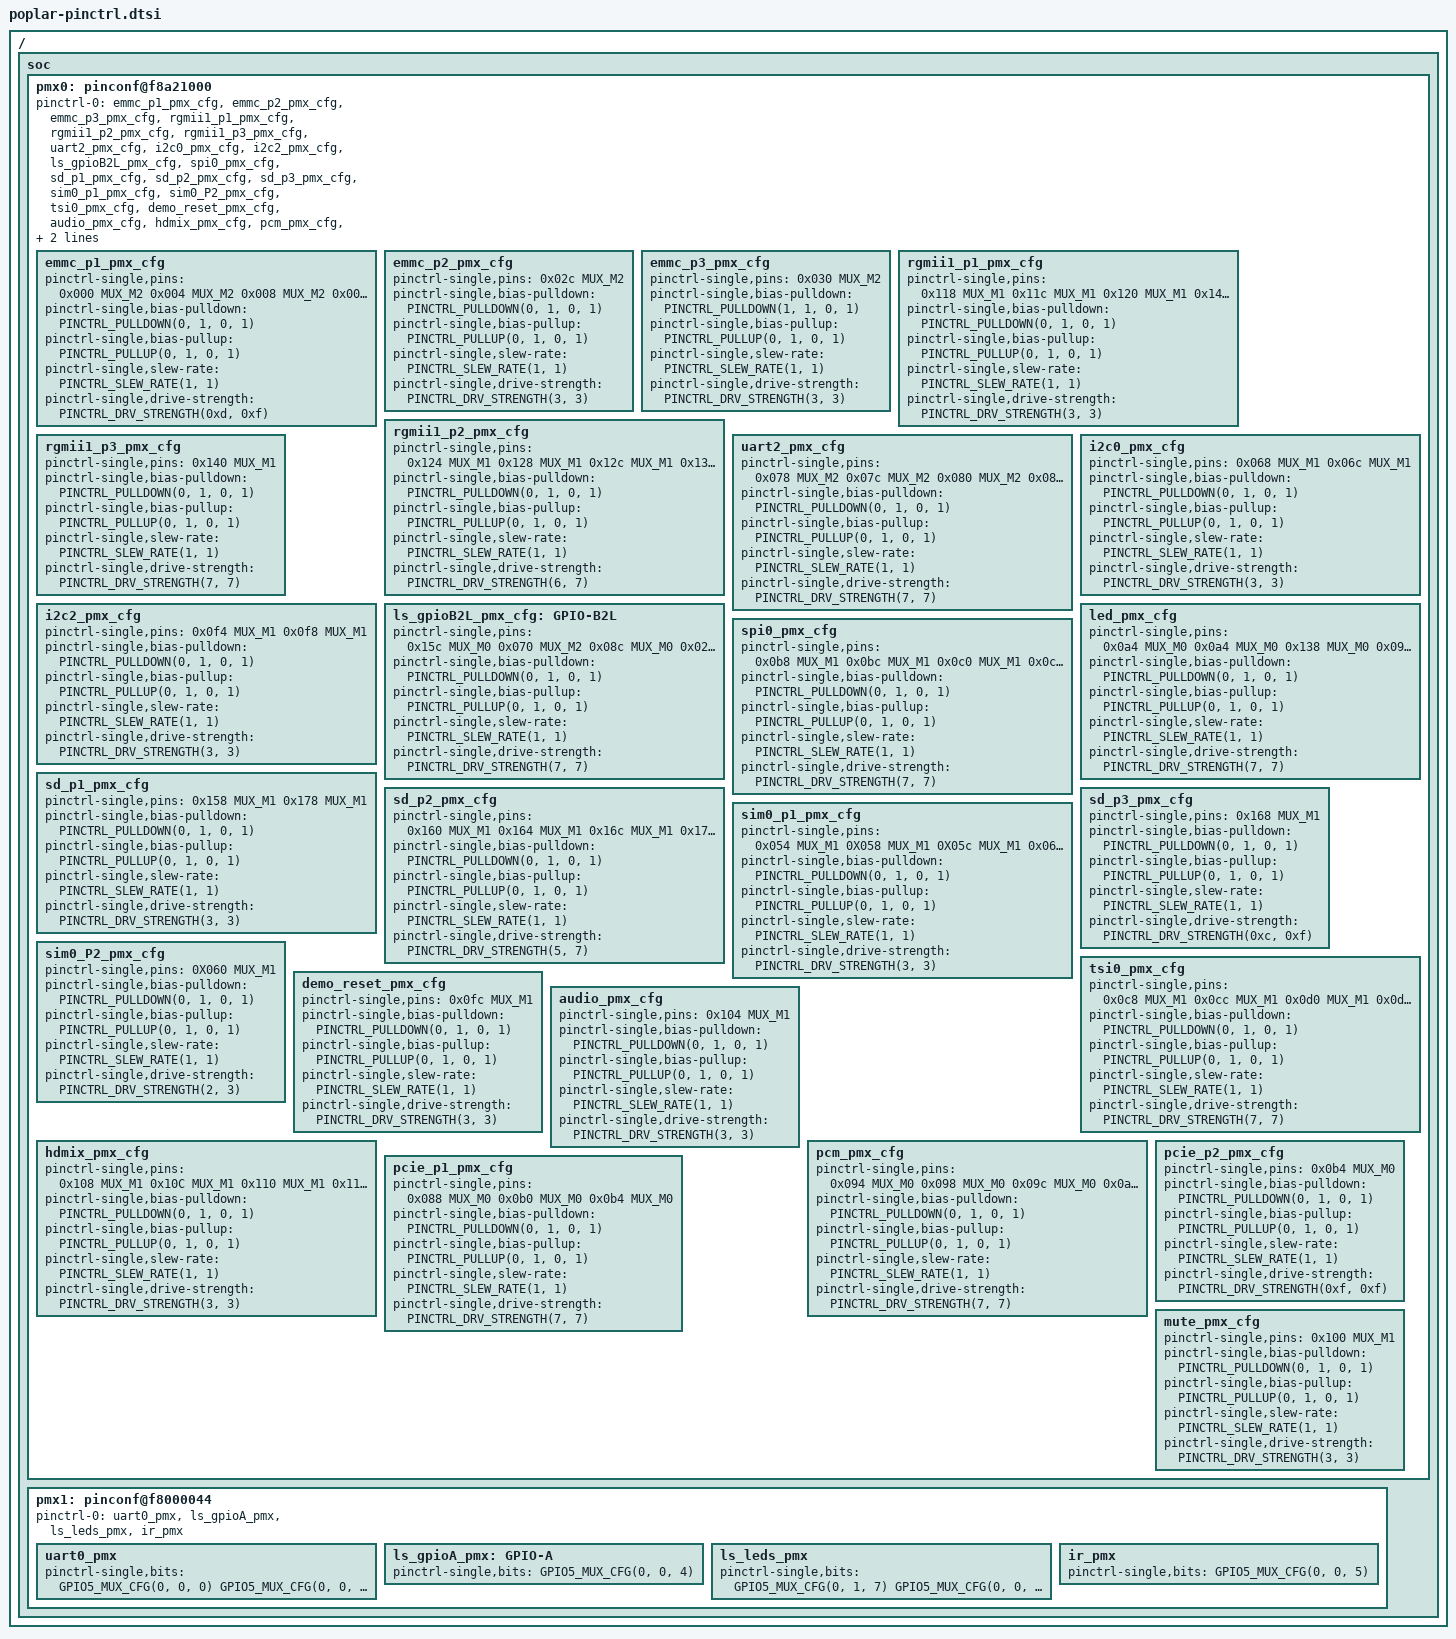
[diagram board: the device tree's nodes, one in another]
/*
 * pinctrl dts file for HiSilicon poplar board
 *
 */

#include <dt-bindings/pinctrl/hisi.h>

/* input, enable bits, disable bits, mask */
#define PINCTRL_PULLDOWN(in, en, dis, mask)	(in << 13) (en << 13) (dis << 13) (mask << 13)
#define PINCTRL_PULLUP(in, en, dis, mask)	(in << 12) (en << 12) (dis << 12) (mask << 12)
#define PINCTRL_SLEW_RATE(val, mask)		(val << 8) (mask << 8)
#define PINCTRL_DRV_STRENGTH(val, mask)		(val << 4) (mask << 4)

#define GPIO5_MUX_CFG(offset, val, bit)		(offset) (val << bit) (1 << bit)

/ {
	soc {
		pmx0: pinconf@f8a21000 {
			pinctrl-names = "default";
			pinctrl-0 = <
				&emmc_p1_pmx_cfg
				&emmc_p2_pmx_cfg
				&emmc_p3_pmx_cfg
				&rgmii1_p1_pmx_cfg
				&rgmii1_p2_pmx_cfg
				&rgmii1_p3_pmx_cfg
				&uart2_pmx_cfg
				&i2c0_pmx_cfg
				&i2c2_pmx_cfg
				&ls_gpioB2L_pmx_cfg
				&spi0_pmx_cfg
				&sd_p1_pmx_cfg
				&sd_p2_pmx_cfg
				&sd_p3_pmx_cfg
				&sim0_p1_pmx_cfg
				&sim0_P2_pmx_cfg
				&tsi0_pmx_cfg
				&demo_reset_pmx_cfg
				&audio_pmx_cfg
				&hdmix_pmx_cfg
				&pcm_pmx_cfg
				&pcie_p1_pmx_cfg
				&pcie_p2_pmx_cfg
				&mute_pmx_cfg
			>;

			emmc_p1_pmx_cfg: emmc_p1_pmx_cfg {
				pinctrl-single,pins = <
					0x000 MUX_M2	/* EMMC_CDATA3 */
					0x004 MUX_M2	/* EMMC_CDATA4 */
					0x008 MUX_M2	/* EMMC_CDATA0 */
					0x00c MUX_M2	/* EMMC_CDATA5 */
					0x010 MUX_M2	/* EMMC_CDATA1 */
					0x014 MUX_M2	/* EMMC_CDATA6 */
					0x018 MUX_M2	/* EMMC_CDATA2 */
					0x01c MUX_M2	/* EMMC_CDATA7 */
					0x024 MUX_M2	/* EMMC_CCMD */
					0x028 MUX_M2	/* EMMC_CCLK_OUT */
				>;
				pinctrl-single,bias-pulldown	= <PINCTRL_PULLDOWN(0, 1, 0, 1)>;
				pinctrl-single,bias-pullup	= <PINCTRL_PULLUP(0, 1, 0, 1)>;
				pinctrl-single,slew-rate	= <PINCTRL_SLEW_RATE(1, 1)>;
				pinctrl-single,drive-strength	= <PINCTRL_DRV_STRENGTH(0xd, 0xf)>;
			};

			emmc_p2_pmx_cfg: emmc_p2_pmx_cfg {
				pinctrl-single,pins = <
					0x02c MUX_M2	/* EMMC_RST */
				>;
				pinctrl-single,bias-pulldown	= <PINCTRL_PULLDOWN(0, 1, 0, 1)>;
				pinctrl-single,bias-pullup	= <PINCTRL_PULLUP(0, 1, 0, 1)>;
				pinctrl-single,slew-rate	= <PINCTRL_SLEW_RATE(1, 1)>;
				pinctrl-single,drive-strength	= <PINCTRL_DRV_STRENGTH(3, 3)>;
			};

			emmc_p3_pmx_cfg: emmc_p3_pmx_cfg {
				pinctrl-single,pins = <
					0x030 MUX_M2	/* EMMC_DATA_STROBE */
				>;
				pinctrl-single,bias-pulldown	= <PINCTRL_PULLDOWN(1, 1, 0, 1)>;
				pinctrl-single,bias-pullup	= <PINCTRL_PULLUP(0, 1, 0, 1)>;
				pinctrl-single,slew-rate	= <PINCTRL_SLEW_RATE(1, 1)>;
				pinctrl-single,drive-strength	= <PINCTRL_DRV_STRENGTH(3, 3)>;
			};

			/* RGMII1 */
			rgmii1_p1_pmx_cfg: rgmii1_p1_pmx_cfg {
				pinctrl-single,pins = <
					0x118 MUX_M1	/* RGMII1_MDIO */
					0x11c MUX_M1	/* RGMII1_MDCK */
					0x120 MUX_M1	/* RGMII1_RST */
					0x144 MUX_M1	/* RGMII1_RXD3 */
					0x148 MUX_M1	/* RGMII1_RXD2 */
					0x14c MUX_M1	/* RGMII1_RXD1 */
					0x150 MUX_M1	/* RGMII1_RXD0 */
					0x154 MUX_M1	/* RGMII1_RXDV */
				>;
				pinctrl-single,bias-pulldown	= <PINCTRL_PULLDOWN(0, 1, 0, 1)>;
				pinctrl-single,bias-pullup	= <PINCTRL_PULLUP(0, 1, 0, 1)>;
				pinctrl-single,slew-rate	= <PINCTRL_SLEW_RATE(1, 1)>;
				pinctrl-single,drive-strength	= <PINCTRL_DRV_STRENGTH(3, 3)>;
			};

			rgmii1_p2_pmx_cfg: rgmii1_p2_pmx_cfg {
				pinctrl-single,pins = <
					0x124 MUX_M1	/* RGMII1_TXEN */
					0x128 MUX_M1	/* RGMII1_TXD3 */
					0x12c MUX_M1	/* RGMII1_TXD2 */
					0x130 MUX_M1	/* RGMII1_TXD1 */
					0x134 MUX_M1	/* RGMII1_TXD0 */
					0x13c MUX_M1	/* RGMII1_TXCK */
				>;
				pinctrl-single,bias-pulldown	= <PINCTRL_PULLDOWN(0, 1, 0, 1)>;
				pinctrl-single,bias-pullup	= <PINCTRL_PULLUP(0, 1, 0, 1)>;
				pinctrl-single,slew-rate	= <PINCTRL_SLEW_RATE(1, 1)>;
				pinctrl-single,drive-strength	= <PINCTRL_DRV_STRENGTH(6, 7)>;
			};

			rgmii1_p3_pmx_cfg: rgmii1_p3_pmx_cfg {
				pinctrl-single,pins = <
					0x140 MUX_M1	/* RGMII1_RXCK */
				>;
				pinctrl-single,bias-pulldown	= <PINCTRL_PULLDOWN(0, 1, 0, 1)>;
				pinctrl-single,bias-pullup	= <PINCTRL_PULLUP(0, 1, 0, 1)>;
				pinctrl-single,slew-rate	= <PINCTRL_SLEW_RATE(1, 1)>;
				pinctrl-single,drive-strength	= <PINCTRL_DRV_STRENGTH(7, 7)>;
			};

			uart2_pmx_cfg: uart2_pmx_cfg {
				pinctrl-single,pins = <
					0x078 MUX_M2	/* UART2_RTSN */
					0x07c MUX_M2	/* UART2_TXD */
					0x080 MUX_M2	/* UART2_RXD */
					0x084 MUX_M2	/* UART2_CTSN */
				>;
				pinctrl-single,bias-pulldown	= <PINCTRL_PULLDOWN(0, 1, 0, 1)>;
				pinctrl-single,bias-pullup	= <PINCTRL_PULLUP(0, 1, 0, 1)>;
				pinctrl-single,slew-rate	= <PINCTRL_SLEW_RATE(1, 1)>;
				pinctrl-single,drive-strength	= <PINCTRL_DRV_STRENGTH(7, 7)>;
			};

			i2c0_pmx_cfg: i2c0_pmx_cfg {
				pinctrl-single,pins = <
					0x068 MUX_M1	/* I2C0_SDA */
					0x06c MUX_M1	/* I2C0_SCL */
				>;
				pinctrl-single,bias-pulldown	= <PINCTRL_PULLDOWN(0, 1, 0, 1)>;
				pinctrl-single,bias-pullup	= <PINCTRL_PULLUP(0, 1, 0, 1)>;
				pinctrl-single,slew-rate	= <PINCTRL_SLEW_RATE(1, 1)>;
				pinctrl-single,drive-strength	= <PINCTRL_DRV_STRENGTH(3, 3)>;
			};

			i2c2_pmx_cfg: i2c2_pmx_cfg {
				pinctrl-single,pins = <
					0x0f4 MUX_M1	/* I2C2_SCL */
					0x0f8 MUX_M1	/* I2C2_SDA */
				>;
				pinctrl-single,bias-pulldown	= <PINCTRL_PULLDOWN(0, 1, 0, 1)>;
				pinctrl-single,bias-pullup	= <PINCTRL_PULLUP(0, 1, 0, 1)>;
				pinctrl-single,slew-rate	= <PINCTRL_SLEW_RATE(1, 1)>;
				pinctrl-single,drive-strength	= <PINCTRL_DRV_STRENGTH(3, 3)>;
			};

			/* GPIO in Low Speed Expansion Connector */
			ls_gpioB2L_pmx_cfg: GPIO-B2L {
				pinctrl-single,pins = <
					0x15c MUX_M0	/* GPIO-B */
					0x070 MUX_M2	/* GPIO-C */
					0x08c MUX_M0	/* GPIO-D */
					0x020 MUX_M0	/* GPIO-E */
					0x034 MUX_M0	/* GPIO-F */
					0x04c MUX_M0	/* GPIO-G */
					0x040 MUX_M0	/* GPIO-H */
					0x044 MUX_M0	/* GPIO-I */
					0x03c MUX_M0	/* GPIO-J */
					0x050 MUX_M0	/* GPIO-K */
					0x048 MUX_M0	/* GPIO-L */
				>;
				pinctrl-single,bias-pulldown	= <PINCTRL_PULLDOWN(0, 1, 0, 1)>;
				pinctrl-single,bias-pullup	= <PINCTRL_PULLUP(0, 1, 0, 1)>;
				pinctrl-single,slew-rate	= <PINCTRL_SLEW_RATE(1, 1)>;
				pinctrl-single,drive-strength	= <PINCTRL_DRV_STRENGTH(7, 7)>;
			};

			led_pmx_cfg: led_pmx_cfg {
				pinctrl-single,pins = <
					0x0a4 MUX_M0	/* WIFI LED */
					0x0a4 MUX_M0	/* USER1 LED */
					0x138 MUX_M0	/* USER4 LED */
					0x090 MUX_M0    /* LED_WIFI */
				>;
				pinctrl-single,bias-pulldown	= <PINCTRL_PULLDOWN(0, 1, 0, 1)>;
				pinctrl-single,bias-pullup	= <PINCTRL_PULLUP(0, 1, 0, 1)>;
				pinctrl-single,slew-rate	= <PINCTRL_SLEW_RATE(1, 1)>;
				pinctrl-single,drive-strength	= <PINCTRL_DRV_STRENGTH(7, 7)>;
			};

			spi0_pmx_cfg: spi0_pmx_cfg {
				pinctrl-single,pins = <
					0x0b8 MUX_M1	/* SPI0_SCLK */
					0x0bc MUX_M1	/* SPI0_CSN */
					0x0c0 MUX_M1	/* SPI0_SDI */
					0x0c4 MUX_M1	/* SPI0_SDO */
				>;
				pinctrl-single,bias-pulldown	= <PINCTRL_PULLDOWN(0, 1, 0, 1)>;
				pinctrl-single,bias-pullup	= <PINCTRL_PULLUP(0, 1, 0, 1)>;
				pinctrl-single,slew-rate	= <PINCTRL_SLEW_RATE(1, 1)>;
				pinctrl-single,drive-strength	= <PINCTRL_DRV_STRENGTH(7, 7)>;
			};

			sd_p1_pmx_cfg: sd_p1_pmx_cfg {
				pinctrl-single,pins = <
					0x158 MUX_M1   /* SDIO0_CARD_POWER_EN */
					0x178 MUX_M1   /* SDIO0_CARD_DETECT */
				>;
				pinctrl-single,bias-pulldown	= <PINCTRL_PULLDOWN(0, 1, 0, 1)>;
				pinctrl-single,bias-pullup	= <PINCTRL_PULLUP(0, 1, 0, 1)>;
				pinctrl-single,slew-rate	= <PINCTRL_SLEW_RATE(1, 1)>;
				pinctrl-single,drive-strength	= <PINCTRL_DRV_STRENGTH(3, 3)>;
			};

			sd_p2_pmx_cfg: sd_p2_pmx_cfg {
				pinctrl-single,pins = <
					0x160 MUX_M1   //SDIO0_CDATA1
					0x164 MUX_M1   //SDIO0_CDATA0
					0x16c MUX_M1   //SDIO0_CCMD
					0x170 MUX_M1   //SDIO0_CDATA3
					0x174 MUX_M1   //SDIO0_CDATA2
				>;
				pinctrl-single,bias-pulldown	= <PINCTRL_PULLDOWN(0, 1, 0, 1)>;
				pinctrl-single,bias-pullup	= <PINCTRL_PULLUP(0, 1, 0, 1)>;
				pinctrl-single,slew-rate	= <PINCTRL_SLEW_RATE(1, 1)>;
				pinctrl-single,drive-strength	= <PINCTRL_DRV_STRENGTH(5, 7)>;
			};

			sd_p3_pmx_cfg: sd_p3_pmx_cfg {
				pinctrl-single,pins = <
					0x168 MUX_M1   //SDIO0_CCLK_OUT
				>;
				pinctrl-single,bias-pulldown	= <PINCTRL_PULLDOWN(0, 1, 0, 1)>;
				pinctrl-single,bias-pullup	= <PINCTRL_PULLUP(0, 1, 0, 1)>;
				pinctrl-single,slew-rate	= <PINCTRL_SLEW_RATE(1, 1)>;
				pinctrl-single,drive-strength	= <PINCTRL_DRV_STRENGTH(0xc, 0xf)>;
			};
			
			sim0_p1_pmx_cfg:sim0_p1_pmx_cfg {
                pinctrl-single,pins = <
	                0x054 MUX_M1    /*SIM0_DET*/
		            0X058 MUX_M1    /*SIM0_DATA*/
		            0X05c MUX_M1    /*SIM0_RST*/
                    0x064 MUX_M1	/*SIM0_PWREN*/				
	            >;
	            pinctrl-single,bias-pulldown    = <PINCTRL_PULLDOWN(0, 1, 0, 1)>;
                pinctrl-single,bias-pullup  = <PINCTRL_PULLUP(0, 1, 0, 1)>;
                pinctrl-single,slew-rate    = <PINCTRL_SLEW_RATE(1, 1)>;
                pinctrl-single,drive-strength   = <PINCTRL_DRV_STRENGTH(3, 3)>;	
            };

            sim0_P2_pmx_cfg:sim0_P2_pmx_cfg {
                pinctrl-single,pins = <
	                0X060 MUX_M1    /*SIM0_CLK*/
	            >;
	            pinctrl-single,bias-pulldown    = <PINCTRL_PULLDOWN(0, 1, 0, 1)>;
	            pinctrl-single,bias-pullup  = <PINCTRL_PULLUP(0, 1, 0, 1)>;
	            pinctrl-single,slew-rate    = <PINCTRL_SLEW_RATE(1, 1)>;
	            pinctrl-single,drive-strength   = <PINCTRL_DRV_STRENGTH(2, 3)>;
            };

            tsi0_pmx_cfg:tsi0_pmx_cfg {
                pinctrl-single,pins = <
	                0x0c8 MUX_M1    /* TSI0_D7 */
		            0x0cc MUX_M1    /* TSI0_D6 */
		            0x0d0 MUX_M1    /* TSI0_D5 */
		            0x0d4 MUX_M1    /* TSI0_D4 */
		            0x0d8 MUX_M1    /* TSI0_D3 */
		            0x0dc MUX_M1    /* TSI0_D2 */
		            0x0e0 MUX_M1    /* TSI0_D1 */
		            0x0e4 MUX_M1    /* TSI0_D0 */
		            0x0e8 MUX_M1    /* TSI0_CLK */
		            0x0ec MUX_M1    /* TSI0_SYNC */
		            0x0f0 MUX_M1    /* TSI0_VALID */
	            >;
	            pinctrl-single,bias-pulldown    = <PINCTRL_PULLDOWN(0, 1, 0, 1)>;
	            pinctrl-single,bias-pullup  = <PINCTRL_PULLUP(0, 1, 0, 1)>;
	            pinctrl-single,slew-rate    = <PINCTRL_SLEW_RATE(1, 1)>;
	            pinctrl-single,drive-strength   = <PINCTRL_DRV_STRENGTH(7, 7)>;
            };

            demo_reset_pmx_cfg:demo_reset_pmx_cfg {
                pinctrl-single,pins = <
	                0x0fc MUX_M1    /* demo_reset */
	            >;
            	pinctrl-single,bias-pulldown    = <PINCTRL_PULLDOWN(0, 1, 0, 1)>;
	            pinctrl-single,bias-pullup  = <PINCTRL_PULLUP(0, 1, 0, 1)>;
	            pinctrl-single,slew-rate    = <PINCTRL_SLEW_RATE(1, 1)>;
	            pinctrl-single,drive-strength   = <PINCTRL_DRV_STRENGTH(3, 3)>;
            };

            audio_pmx_cfg:audio_pmx_cfg {
                pinctrl-single,pins = <
	                0x104 MUX_M1    /* SPDIF_OUT */
	            >;
	            pinctrl-single,bias-pulldown    = <PINCTRL_PULLDOWN(0, 1, 0, 1)>;
	            pinctrl-single,bias-pullup  = <PINCTRL_PULLUP(0, 1, 0, 1)>;
	            pinctrl-single,slew-rate    = <PINCTRL_SLEW_RATE(1, 1)>;
	            pinctrl-single,drive-strength   = <PINCTRL_DRV_STRENGTH(3, 3)>;
            };

            hdmix_pmx_cfg:hdmix_pmx_cfg {
                pinctrl-single,pins = <
	                0x108 MUX_M1    /* HDMITX_HOTPLUG*/
	            	0x10C MUX_M1    /* HDMITX_SDA */
	               	0x110 MUX_M1    /* HDMITX_SCL */
	              	0x114 MUX_M1    /* HDMITX_CEC */
	            >;
	            pinctrl-single,bias-pulldown    = <PINCTRL_PULLDOWN(0, 1, 0, 1)>;
	            pinctrl-single,bias-pullup  = <PINCTRL_PULLUP(0, 1, 0, 1)>;
	            pinctrl-single,slew-rate    = <PINCTRL_SLEW_RATE(1, 1)>;
	            pinctrl-single,drive-strength   = <PINCTRL_DRV_STRENGTH(3, 3)>;
            };
			
			pcm_pmx_cfg:pcm_pmx_cfg {
			    pinctrl-single,pins = <
				    0x094 MUX_M0    /* PCM_SYNC */
					0x098 MUX_M0    /* PCM_OUT */
					0x09c MUX_M0    /* PCM_CLK */
					0x0a0 MUX_M0    /* PCM_IN */
				>;
				pinctrl-single,bias-pulldown    = <PINCTRL_PULLDOWN(0, 1, 0, 1)>;
				pinctrl-single,bias-pullup  = <PINCTRL_PULLUP(0, 1, 0, 1)>;
				pinctrl-single,slew-rate    = <PINCTRL_SLEW_RATE(1, 1)>;
				pinctrl-single,drive-strength   = <PINCTRL_DRV_STRENGTH(7, 7)>;
			};
			
			pcie_p1_pmx_cfg:pcie_p1_pmx_cfg {
			    pinctrl-single,pins = <
				    0x088 MUX_M0    /* PCIE_RST */
					0x0b0 MUX_M0    /* CPU_WAKE_PCIE */
					0x0b4 MUX_M0    /* PCIE_PWR_EN */
				>;
				pinctrl-single,bias-pulldown    = <PINCTRL_PULLDOWN(0, 1, 0, 1)>;
				pinctrl-single,bias-pullup  = <PINCTRL_PULLUP(0, 1, 0, 1)>;
				pinctrl-single,slew-rate    = <PINCTRL_SLEW_RATE(1, 1)>;
				pinctrl-single,drive-strength   = <PINCTRL_DRV_STRENGTH(7, 7)>;
			};
			
			pcie_p2_pmx_cfg:pcie_p2_pmx_cfg {
			    pinctrl-single,pins = <
					0x0b4 MUX_M0    /* PCIE_PWR_EN */
				>;
				pinctrl-single,bias-pulldown    = <PINCTRL_PULLDOWN(0, 1, 0, 1)>;
				pinctrl-single,bias-pullup  = <PINCTRL_PULLUP(0, 1, 0, 1)>;
				pinctrl-single,slew-rate    = <PINCTRL_SLEW_RATE(1, 1)>;
				pinctrl-single,drive-strength   = <PINCTRL_DRV_STRENGTH(0xf, 0xf)>;
			};
			
			mute_pmx_cfg:mute_pmx_cfg {
			    pinctrl-single,pins = <
				    0x100 MUX_M1    /* MUTE */
				>;
				pinctrl-single,bias-pulldown    = <PINCTRL_PULLDOWN(0, 1, 0, 1)>;
				pinctrl-single,bias-pullup  = <PINCTRL_PULLUP(0, 1, 0, 1)>;
				pinctrl-single,slew-rate    = <PINCTRL_SLEW_RATE(1, 1)>;
				pinctrl-single,drive-strength   = <PINCTRL_DRV_STRENGTH(3, 3)>;
			};
		};

		pmx1: pinconf@f8000044 {
			pinctrl-names = "default";
			pinctrl-0 = <
				&uart0_pmx
				&ls_gpioA_pmx
				&ls_leds_pmx
				&ir_pmx
			>;

			uart0_pmx: uart0_pmx {
				pinctrl-single,bits = <
					GPIO5_MUX_CFG(0, 0, 0)
					GPIO5_MUX_CFG(0, 0, 1)
				>;
			};

			ls_gpioA_pmx: GPIO-A {
				pinctrl-single,bits = <
					GPIO5_MUX_CFG(0, 0, 4)
				>;
			};

			ls_leds_pmx: ls_leds_pmx {
				pinctrl-single,bits = <
					GPIO5_MUX_CFG(0, 1, 7)	/* Bluetooth LED */
					GPIO5_MUX_CFG(0, 0, 3)	/* USER2 LED */
					GPIO5_MUX_CFG(0, 0, 6)	/* USER3 LED */
				>;
			};

			ir_pmx: ir_pmx {
				pinctrl-single,bits = <
					GPIO5_MUX_CFG(0, 0, 5)
				>;
			};
		};
	};
};
